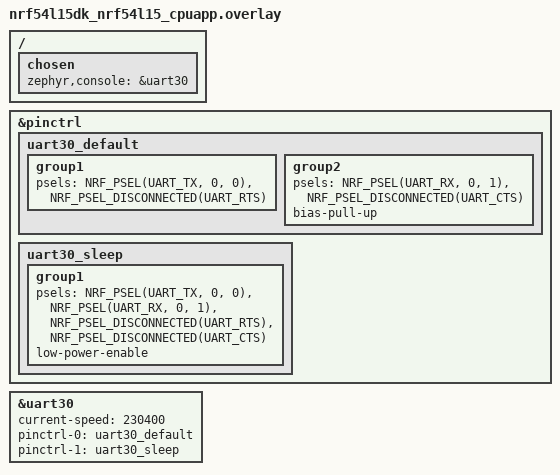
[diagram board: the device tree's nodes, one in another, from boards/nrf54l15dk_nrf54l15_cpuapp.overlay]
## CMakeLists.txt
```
#
# Copyright (c) 2026 Nordic Semiconductor ASA
#
# SPDX-License-Identifier: LicenseRef-Nordic-5-Clause
#

cmake_minimum_required(VERSION 3.20.0)

find_package(Zephyr REQUIRED HINTS $ENV{ZEPHYR_BASE})
project(ipt_initiator)

# NORDIC SDK APP START
target_sources(app PRIVATE
	src/main.c
	src/cs_uart_binary.c
)
# NORDIC SDK APP END
```

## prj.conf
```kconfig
#
# Copyright (c) 2026 Nordic Semiconductor ASA
#
# SPDX-License-Identifier: LicenseRef-Nordic-5-Clause
#

CONFIG_NCS_SAMPLES_DEFAULTS=y
CONFIG_DK_LIBRARY=y

CONFIG_BT=y
CONFIG_BT_SMP=y
CONFIG_BT_CENTRAL=y
CONFIG_BT_MAX_CONN=1
CONFIG_BT_BONDABLE=n

CONFIG_BT_CHANNEL_SOUNDING=y

CONFIG_BT_SCAN=y
CONFIG_BT_SCAN_FILTER_ENABLE=y
CONFIG_BT_SCAN_NAME_CNT=1

# This reduces RAM usage. Additional RAM is needed to support optional
# features such as mode 3 or multiantenna. Change or remove these if
# using those features
CONFIG_BT_CS_DE_MAX_NUM_ANTENNA_PATHS=1
CONFIG_BT_CTLR_SDC_CS_MAX_ANTENNA_PATHS=1
CONFIG_BT_CTLR_SDC_CS_NUM_ANTENNAS=1
CONFIG_BT_CTLR_SDC_CS_STEP_MODE3=n
CONFIG_BT_CTLR_SDC_CS_ROLE_INITIATOR_ONLY=y

# This is required for CS Enhancements
CONFIG_BT_CTLR_EXTENDED_FEAT_SET=y

# Disabling the CS Test command reduces flash usage
CONFIG_BT_CTLR_CHANNEL_SOUNDING_TEST=n

# This allows CS and ACL to use different PHYs
CONFIG_BT_TRANSMIT_POWER_CONTROL=y

# This improves the performance of floating-point operations
CONFIG_FPU=y
CONFIG_FPU_SHARING=y

CONFIG_CBPRINTF_FP_SUPPORT=y

CONFIG_BT_CS_DE=y
CONFIG_BT_CS_DE_1024_NFFT=y

# Binary IQ capture on console UART: keep ASCII logs at WARN+ to avoid frame tear
CONFIG_LOG=y
CONFIG_LOG_DEFAULT_LEVEL=2
```

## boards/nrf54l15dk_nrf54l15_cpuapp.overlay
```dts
/*
 * IPT initiator capture UART: 230400 on uart30 (same physical path as 301ini_Dip).
 *
 * SPDX-License-Identifier: LicenseRef-Nordic-5-Clause
 */

/ {
	chosen {
		/delete-property/ zephyr,console;
		/delete-property/ zephyr,shell-uart;
		/delete-property/ zephyr,uart-mcumgr;
		/delete-property/ zephyr,bt-mon-uart;
		/delete-property/ zephyr,bt-c2h-uart;
		zephyr,console = &uart30;
	};
};

&pinctrl {
	uart30_default: uart30_default {
		group1 {
			psels = <NRF_PSEL(UART_TX, 0, 0)>,
				<NRF_PSEL_DISCONNECTED(UART_RTS)>;
		};
		group2 {
			psels = <NRF_PSEL(UART_RX, 0, 1)>,
				<NRF_PSEL_DISCONNECTED(UART_CTS)>;
			bias-pull-up;
		};
	};

	uart30_sleep: uart30_sleep {
		group1 {
			psels = <NRF_PSEL(UART_TX, 0, 0)>,
				<NRF_PSEL(UART_RX, 0, 1)>,
				<NRF_PSEL_DISCONNECTED(UART_RTS)>,
				<NRF_PSEL_DISCONNECTED(UART_CTS)>;
			low-power-enable;
		};
	};
};

&uart30 {
	current-speed = <230400>;
	pinctrl-0 = <&uart30_default>;
	pinctrl-1 = <&uart30_sleep>;
	pinctrl-names = "default", "sleep";
	/delete-property/ rts-pin;
	/delete-property/ cts-pin;
	status = "okay";
};
```

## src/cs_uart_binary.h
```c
/**
 * @file cs_uart_binary.h
 * @brief DIP / 全功能 CS 共用的 UART 二进制传输层（与业务组帧解耦）
 *
 * 职责边界：
 *   - 本模块只负责「已组好帧」的 CRC 辅助、入队与 uart_poll_out 发送；
 *   - 不解析蓝牙 HCI、不访问 cs_de_report、不决定 IQ 语义。
 *
 * 组帧方（上层）：
 *   - DIP 本地 IQ（type 0x01）/ CS 双端（type 0x02）：见 301ini_Dip
 *   - IPT 已合成 IQ（type 0x03）：本工程 main.c 按 procedure 组帧
 *
 * 传输层与 301ini_Dip/src/cs_uart_binary.* 同源；帧类型 0x03 为 IPT 专用。
 */

#ifndef CS_UART_BINARY_H
#define CS_UART_BINARY_H

#include <stddef.h>
#include <stdint.h>

/** 帧同步字节 1；与 sync2 组合供 PC 端在串口流中定位帧起点 */
#define CS_UART_BIN_SYNC1 0x55U
/** 帧同步字节 2 */
#define CS_UART_BIN_SYNC2 0xAAU
/** 协议版本号；帧头字段含义变更时递增，PC 端可据此分支解析 */
#define CS_UART_BIN_VERSION 0x02U

/** 信道位图字节数：75 个 fft 格点 → ceil(75/8)=10 字节（80 bit，高 5 bit 保留） */
#define CS_UART_BIN_CHANNEL_BITMAP_BYTES 10U
/** fft 信道下标上界（不含）；与 cs_de.c NUM_CHANNELS、DIP_MAX_FFT_CHANNELS 对齐 */
#define CS_UART_BIN_MAX_FFT_CHANNELS 75U

/**
 * 单帧最大长度上界。
 * 头(30) + 全信道双端 IQ(75×8=600) + CRC(2) = 632，取 640 留余量。
 * DIP 本地帧（75×4）亦在此上限内。
 */
#define CS_UART_BIN_MAX_FRAME_SIZE 640U

/** 固定头字节数（含 10 字节 channel_bitmap） */
#define CS_UART_BIN_HEADER_SIZE 30U

/**
 * payload_len 中 procedure_counter 之后、IQ 区之前的固定字节数：
 * timestamp_ms(8) + ap/iq_format/channel_count/reserved(4) + bitmap(10)
 */
#define CS_UART_BIN_PAYLOAD_META_BYTES 22U

/** 帧类型：DIP 本地 IQ，每有效信道 4 字节（int16 i + int16 q） */
#define CS_UART_BIN_TYPE_DIP_LOCAL_IQ 0x01U
/** 帧类型：全功能 CS 双端 IQ，每有效信道 8 字节（i_local,q_local,i_remote,q_remote） */
#define CS_UART_BIN_TYPE_CS_DUAL_IQ 0x02U
/** 帧类型：IPT 已合成 IQ（相位已是 2θ_CH），每有效信道 4 字节（int16 i + int16 q） */
#define CS_UART_BIN_TYPE_IPT_COMBINED_IQ 0x03U

/** iq_format 字段：0 表示 IQ 载荷为有符号 int16、little-endian */
#define CS_UART_BIN_IQ_FORMAT_INT16 0U

/**
 * 发送路径选择（须在编译 cs_uart_binary.c 前与各路径宏保持一致）：
 *   1 — Producer 仅 k_msgq_put(K_NO_WAIT)，Consumer 线程 cs_uart_tx 负责 uart_poll_out；
 *   0 — cs_uart_bin_enqueue_frame() 内直接阻塞发送（便于对比，不推荐量产采集）。
 */
#ifndef CS_UART_BIN_USE_THREAD
#define CS_UART_BIN_USE_THREAD 1
#endif

/**
 * @brief 二进制 UART 帧固定头（packed，无编译器填充）
 *
 * 内存布局（30 字节）后紧接变长 IQ 区，再跟 2 字节 CRC16-CCITT（LE）。
 * IQ 区不嵌入本结构体；组帧时先写头与 IQ，再对 [sync1 .. IQ末] 算 CRC。
 *
 * payload_len：从 procedure_counter 首字节到 IQ 区最后一字节的长度（不含 sync..type、
 *               payload_len 自身、CRC）。
 * timestamp_ms：k_uptime_get() 毫秒，自系统启动的全局单调时钟。
 */
struct __packed cs_uart_bin_header {
  uint8_t sync1;
  uint8_t sync2;
  uint8_t version;
  uint8_t type;
  uint16_t payload_len;
  /** DIP：CS procedure_counter；CS 双端：RAS ranging_counter */
  uint16_t procedure_counter;
  uint64_t timestamp_ms;
  uint8_t ap;
  uint8_t iq_format;
  uint8_t channel_count;
  uint8_t reserved;
  uint8_t channel_bitmap[CS_UART_BIN_CHANNEL_BITMAP_BYTES];
};

/**
 * @brief CRC16-CCITT（多项式 0x1021，初值 0xFFFF）
 * @param data 参与校验的数据首地址
 * @param len  字节长度
 * @return 16 位 CRC；data 为 NULL 时返回初值 0xFFFF
 *
 * 覆盖范围须与 PC 端一致：从帧首 sync1 到 IQ 区最后一字节（不含 CRC 两字节）。
 */
uint16_t cs_uart_bin_crc16_ccitt(const uint8_t *data, size_t len);

/**
 * @brief 经 console UART 逐字节阻塞发送
 * @param data 待发送缓冲区；NULL 或 len==0 时直接返回
 * @param len  字节数
 *
 * 使用 Zephyr uart_poll_out；设备未就绪时静默返回。
 * 线程版在 cs_uart_tx 中调用；阻塞回退路径在 Producer 上下文调用。
 */
void cs_uart_bin_send_bytes(const uint8_t *data, size_t len);

/**
 * @brief 将完整帧交给传输层（入队或直发）
 * @param frame 已组好的帧（含 CRC）
 * @param len   帧长度，须 ≤ CS_UART_BIN_MAX_FRAME_SIZE
 * @return 0 成功；-EINVAL 参数无效；-ENOMEM 队列满（线程模式下丢帧，不阻塞）
 */
int cs_uart_bin_enqueue_frame(const uint8_t *frame, uint16_t len);

/**
 * @brief 启动 cs_uart_tx 发送线程
 *
 * 须在 main() 中 bt_enable() 之前调用一次；重复调用无害。
 * CS_UART_BIN_USE_THREAD=0 时仅打日志，不创建线程。
 */
void cs_uart_bin_tx_thread_start(void);

#endif /* CS_UART_BINARY_H */
```
